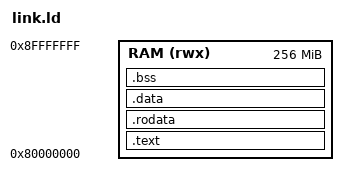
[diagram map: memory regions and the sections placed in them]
/* Simple linker script for Shuttle test programs */

ENTRY(_start)

MEMORY
{
    RAM (rwx) : ORIGIN = 0x80000000, LENGTH = 256M
}

SECTIONS
{
    .text : {
        *(.text)
        *(.text.*)
    } > RAM

    .rodata : {
        *(.rodata)
        *(.rodata.*)
    } > RAM

    .data : {
        *(.data)
        *(.data.*)
    } > RAM

    .bss : {
        *(.bss)
        *(.bss.*)
    } > RAM
}
